# GD32F527 register map
File version: 1.0
CPU: CM33 r0p1, little endian, MPU, FPU, 4 interrupt priority bits
Registers are 32-bit, read-write, reset 0x0 unless marked. A register's access mark holds for its fields unless they carry their own. Offsets are from the block's base; [hi:lo] are bit positions; {n}, {i} and the like mark numbered series.

## TIMER0 — Advanced timer
Base 0x40010000
Same registers: TIMER7 0x40010400
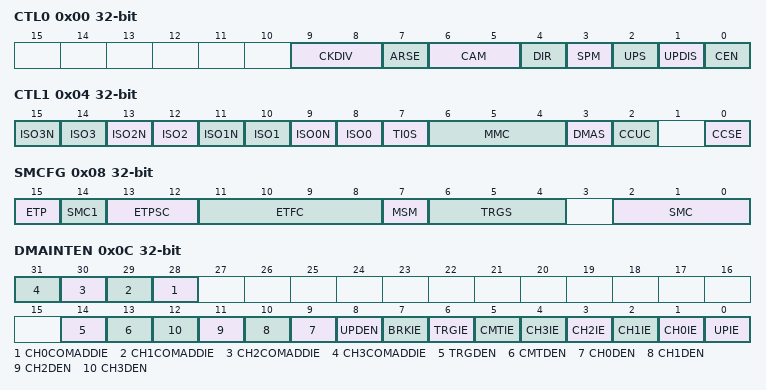
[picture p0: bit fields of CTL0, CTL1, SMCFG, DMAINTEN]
0x00 CTL0 — Control register 0
  [9:8] CKDIV — Clock division
  [7] ARSE — Auto-reload shadow enable
  [6:5] CAM — Counter aligns mode selection
  [4] DIR — Direction
  [3] SPM — Single pulse mode.
  [2] UPS — Update source
  [1] UPDIS — Update disable.
  [0] CEN — Counter enable
0x04 CTL1 — Control register 1
  [2n+9] ISO{n}N (n=0..3) — Idle state of channel {n} complementary output
  [2n+8] ISO{n} (n=0..3) — Idle state of channel {n} output
  [7] TI0S — Channel 0 trigger input selection
  [6:4] MMC — Master mode control
  [3] DMAS — DMA request source selection
  [2] CCUC — Commutation control shadow register update control
  [0] CCSE — Commutation control shadow enable
0x08 SMCFG — Slave mode configuration register
  [15] ETP — External trigger polarity
  [14] SMC1 — Part of SMC for enable External clock mode1.
  [13:12] ETPSC — The prescaler of external trigger
  [11:8] ETFC — External trigger filter control
  [7] MSM — Master-slave mode
  [6:4] TRGS — Trigger selection
  [2:0] SMC — Slave mode control
0x0C DMAINTEN — DMA and interrupt enable register
  [n+28] CH{n}COMADDIE (n=0..3) — Channel {n} additional compare interrupt enable
  [14] TRGDEN — Trigger DMA request enable
  [13] CMTDEN — Commutation DMA request enable
  [n+9] CH{n}DEN (n=0..3) — Channel {n} capture/compare DMA request enable
  [8] UPDEN — Update DMA request enable
  [7] BRKIE — Break interrupt enable
  [6] TRGIE — Trigger interrupt enable
  [5] CMTIE — commutation interrupt enable
  [n+1] CH{n}IE (n=0..3) — Channel {n} capture/compare interrupt enable
  [0] UPIE — Update interrupt enable
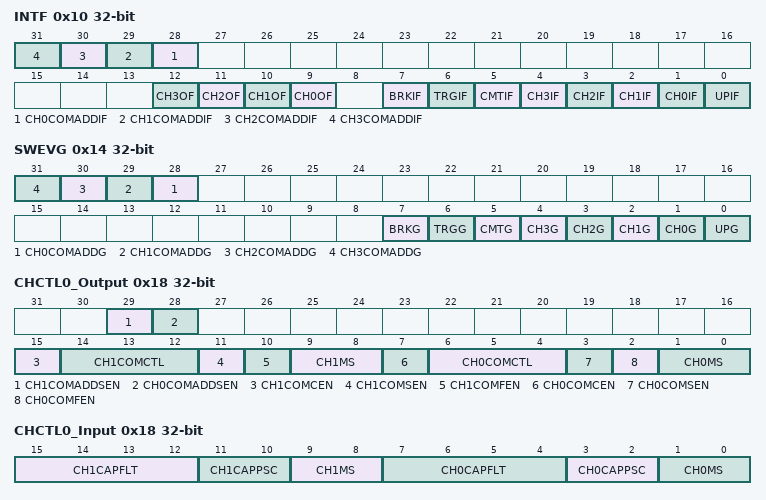
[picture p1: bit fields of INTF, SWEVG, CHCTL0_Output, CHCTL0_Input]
0x10 INTF — Interrupt flag register
  [n+28] CH{n}COMADDIF (n=0..3) — Channel {n} additional compare interrupt flag.
  [n+9] CH{n}OF (n=0..3) — Channel {n} over capture flag
  [7] BRKIF — Break interrupt flag
  [6] TRGIF — Trigger interrupt flag
  [5] CMTIF — Channel commutation interrupt flag
  [n+1] CH{n}IF (n=0..3) — Channel {n} capture/compare interrupt flag
  [0] UPIF — Update interrupt flag
0x14 SWEVG wo — Software event generation register
  [n+28] CH{n}COMADDG (n=0..3) — Channel {n} additional compare event generation.
  [7] BRKG — Break event generation
  [6] TRGG — Trigger event generation
  [5] CMTG — Channel commutation event generation
  [n+1] CH{n}G (n=0..3) — Channel {n} capture or compare event generation
  [0] UPG — Update event generation
0x18 CHCTL0_Output — Channel control register 0 (output mode)
  [29] CH1COMADDSEN — Channel 1 additional compare output shadow enable
  [28] CH0COMADDSEN — Channel 0 additional compare output shadow enable
  [15] CH1COMCEN — Channel 1 output compare clear enable
  [14:12] CH1COMCTL — Channel 1 compare output control
  [11] CH1COMSEN — Channel 1 output compare shadow enable
  [10] CH1COMFEN — Channel 1 output compare fast enable
  [9:8] CH1MS — Channel 1 mode selection
  [7] CH0COMCEN — Channel 0 output compare clear enable
  [6:4] CH0COMCTL — Channel 0 compare output control
  [3] CH0COMSEN — Channel 0 compare output shadow enable
  [2] CH0COMFEN — Channel 0 output compare fast enable
  [1:0] CH0MS — Channel 0 I/O mode selection
0x18 CHCTL0_Input (alternate view of CHCTL0_Output) — Channel control register 0 (input mode)
  [15:12] CH1CAPFLT — Channel 1 input capture filter control
  [11:10] CH1CAPPSC — Channel 1 input capture prescaler
  [9:8] CH1MS — Channel 1 mode selection
  [7:4] CH0CAPFLT — Channel 0 input capture filter control
  [3:2] CH0CAPPSC — Channel 0 input capture prescaler
  [1:0] CH0MS — Channel 0 mode selection
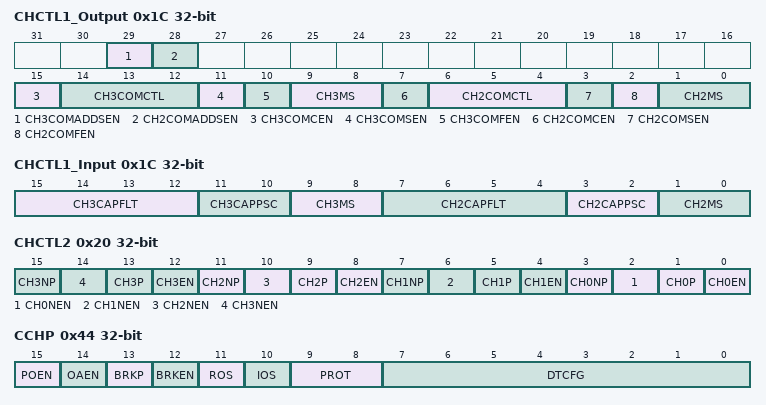
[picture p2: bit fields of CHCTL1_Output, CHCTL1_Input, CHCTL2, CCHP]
0x1C CHCTL1_Output — Channel control register 1 (output mode)
  [29] CH3COMADDSEN — Channel 3 additional compare output shadow enable
  [28] CH2COMADDSEN — Channel 2 additional compare output shadow enable
  [15] CH3COMCEN — Channel 3 output compare clear enable
  [14:12] CH3COMCTL — Channel 3 compare output control
  [11] CH3COMSEN — Channel 3 output compare shadow enable
  [10] CH3COMFEN — Channel 3 output compare fast enable
  [9:8] CH3MS — Channel 3 mode selection
  [7] CH2COMCEN — Channel 2 output compare clear enable
  [6:4] CH2COMCTL — Channel 2 compare output control
  [3] CH2COMSEN — Channel 2 compare output shadow enable
  [2] CH2COMFEN — Channel 2 output compare fast enable
  [1:0] CH2MS — Channel 2 I/O mode selection
0x1C CHCTL1_Input (alternate view of CHCTL1_Output) — Channel control register 1 (input mode)
  [15:12] CH3CAPFLT — Channel 3 input capture filter control
  [11:10] CH3CAPPSC — Channel 3 input capture prescaler
  [9:8] CH3MS — Channel 3 mode selection
  [7:4] CH2CAPFLT — Channel 2 input capture filter control
  [3:2] CH2CAPPSC — Channel 2 input capture prescaler
  [1:0] CH2MS — Channel 2 mode selection
0x20 CHCTL2 — Channel control register 2
  [4n+3] CH{n}NP (n=0..3) — Channel {n} complementary output polarity
  [4n+2] CH{n}NEN (n=0..3) — Channel {n} complementary output enable
  [4n+1] CH{n}P (n=0..3) — Channel {n} capture/compare function polarity
  [4n] CH{n}EN (n=0..3) — Channel {n} capture/compare function enable
0x24 CNT — Counter register
  [15:0] CNT — This bit-filed indicates the current counter value. Writing to this bit-filed can change the value of the counter.
0x28 PSC — Prescaler register
  [15:0] PSC — Prescaler value of the counter clock
0x2C CAR reset 0xFFFF — Counter auto reload register
  [15:0] CARL — Counter auto reload value
0x30 CREP — Counter repetition register
  [7:0] CREP — Counter repetition value
0x34 CH0CV — Channel 0 capture/compare value register
  [15:0] CH0VAL — Capture or compare value of channel0
0x38 CH1CV — Channel 1 capture/compare value register
  [15:0] CH1VAL — Capture or compare value of channel1
0x3C CH2CV — Channel 2 capture/compare value register
  [15:0] CH2VAL — Capture or compare value of channel 2
0x40 CH3CV — Channel 3 capture/compare value register
  [15:0] CH3VAL — Capture or compare value of channel 3
0x44 CCHP — Complementary channel protection register
  [15] POEN — Primary output enable
  [14] OAEN — Output automatic enable
  [13] BRKP — Break input polarity
  [12] BRKEN — Break input enable
  [11] ROS — Run mode off-state enable
  [10] IOS — Idle mode off-state enable
  [9:8] PROT — Complementary register protect control
  [7:0] DTCFG — Dead time configure
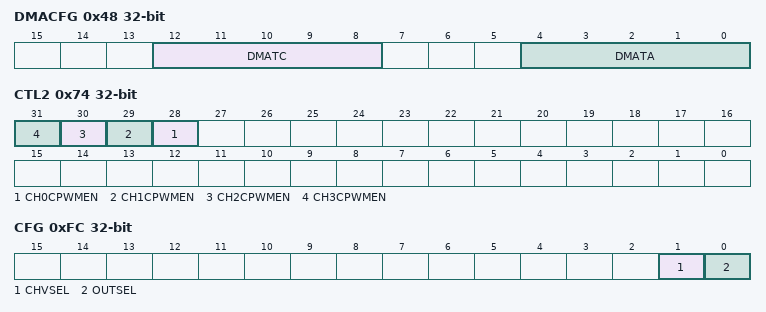
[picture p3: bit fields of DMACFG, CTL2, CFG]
0x48 DMACFG — DMA configuration register
  [12:8] DMATC — DMA transfer count
  [4:0] DMATA — DMA transfer access start address
0x4C DMATB — DMA transfer buffer register
  [15:0] DMATB — DMA transfer buffer
{0x64+4i} CH{i}COMV_ADD (i=0..3) — Channel {i} additional compare value register
  [15:0] CH{i}COMVAL_ADD — Additional compare value of channel {i}
0x74 CTL2 — Control register 2
  [n+28] CH{n}CPWMEN (n=0..3) — Channel {n} composite PWM mode enable
0xFC CFG — Configuration register
  [1] CHVSEL — Write CHxVAL register selection
  [0] OUTSEL — The output value selection
